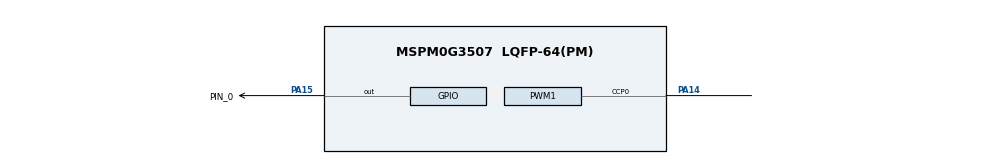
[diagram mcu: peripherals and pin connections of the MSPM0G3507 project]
/**
 * These arguments were used when this file was generated. They will be automatically applied on subsequent loads
 * via the GUI or CLI. Run CLI with '--help' for additional information on how to override these arguments.
 * @cliArgs --device "MSPM0G350X" --part "Default" --package "LQFP-64(PM)" --product "mspm0_sdk@2.10.00.04"
 * @v2CliArgs --device "MSPM0G3507" --package "LQFP-64(PM)" --product "mspm0_sdk@2.10.00.04"
 * @versions {"tool":"1.27.1+4634"}
 */

/**
 * Import the modules used in this configuration.
 */
const ADC12   = scripting.addModule("/ti/driverlib/ADC12", {}, false);
const ADC121  = ADC12.addInstance();
const GPIO    = scripting.addModule("/ti/driverlib/GPIO", {}, false);
const GPIO1   = GPIO.addInstance();
const PWM     = scripting.addModule("/ti/driverlib/PWM", {}, false);
const PWM1    = PWM.addInstance();
const SYSCTL  = scripting.addModule("/ti/driverlib/SYSCTL");
const SYSTICK = scripting.addModule("/ti/driverlib/SYSTICK");

/**
 * Write custom configuration values to the imported modules.
 */
ADC121.$name                             = "ADC12_0";
ADC121.sampClkDiv                        = "DL_ADC12_CLOCK_DIVIDE_8";
ADC121.configureDMA                      = true;
ADC121.samplingOperationMode             = "sequence";
ADC121.repeatMode                        = true;
ADC121.enableFIFO                        = true;
ADC121.adcMem1chansel                    = "DL_ADC12_INPUT_CHAN_1";
ADC121.endAdd                            = 1;
ADC121.powerDownMode                     = "DL_ADC12_POWER_DOWN_MODE_MANUAL";
ADC121.enabledDMATriggers                = ["DL_ADC12_DMA_MEM0_RESULT_LOADED"];
ADC121.enabledInterrupts                 = ["DL_ADC12_INTERRUPT_DMA_DONE"];
ADC121.sampleTime0                       = "1 ms";
ADC121.sampCnt                           = 1;
ADC121.adcPin0Config.$name               = "ti_driverlib_gpio_GPIOPinGeneric1";
ADC121.DMA_CHANNEL.$name                 = "DMA_CH0";
ADC121.DMA_CHANNEL.addressMode           = "f2b";
ADC121.DMA_CHANNEL.configureTransferSize = true;
ADC121.DMA_CHANNEL.transferMode          = "FULL_CH_REPEAT_BLOCK";
ADC121.DMA_CHANNEL.transferSize          = 10;
ADC121.DMA_CHANNEL.peripheral.$assign    = "DMA_CH0";
ADC121.peripheral.$assign                = "ADC0";
ADC121.peripheral.adcPin0.$assign        = "PA27";
ADC121.peripheral.adcPin1.$assign        = "PA26";
ADC121.adcPin1Config.$name               = "ti_driverlib_gpio_GPIOPinGeneric2";

const Board = scripting.addModule("/ti/driverlib/Board", {}, false);

GPIO1.$name                         = "GPIO_GRP_0";
GPIO1.port                          = "PORTA";
GPIO1.associatedPins.create(2);
GPIO1.associatedPins[0].$name       = "PIN_0";
GPIO1.associatedPins[0].assignedPin = "15";
GPIO1.associatedPins[0].pin.$assign = "PA15";
GPIO1.associatedPins[1].$name       = "PIN_1";
GPIO1.associatedPins[1].direction   = "INPUT";
GPIO1.associatedPins[1].assignedPin = "18";

PWM1.$name                      = "PWM_0";
PWM1.clockDivider               = 8;
PWM1.pwmMode                    = "EDGE_ALIGN_UP";
PWM1.ccIndex                    = [0];
PWM1.timerCount                 = 4000;
PWM1.PWM_CHANNEL_0.$name        = "ti_driverlib_pwm_PWMTimerCC0";
PWM1.PWM_CHANNEL_0.dutyCycle    = 50;
PWM1.ccp0PinConfig.$name        = "ti_driverlib_gpio_GPIOPinGeneric0";
PWM1.peripheral.$assign         = "TIMG12";
PWM1.peripheral.ccp0Pin.$assign = "PA14";

SYSCTL.forceDefaultClkConfig = true;
SYSCTL.clockTreeEn           = true;

SYSTICK.periodEnable    = true;
SYSTICK.period          = 32000;
SYSTICK.interruptEnable = true;

/**
 * Pinmux solution for unlocked pins/peripherals. This ensures that minor changes to the automatic solver in a future
 * version of the tool will not impact the pinmux you originally saw.  These lines can be completely deleted in order to
 * re-solve from scratch.
 */
Board.peripheral.$suggestSolution            = "DEBUGSS";
Board.peripheral.swclkPin.$suggestSolution   = "PA20";
Board.peripheral.swdioPin.$suggestSolution   = "PA19";
GPIO1.associatedPins[1].pin.$suggestSolution = "PA18";
